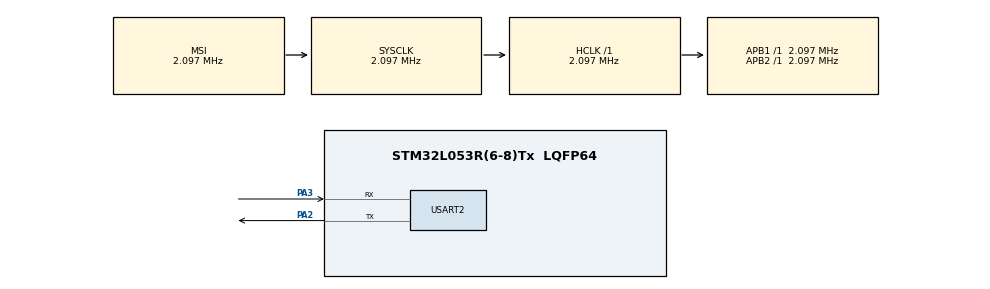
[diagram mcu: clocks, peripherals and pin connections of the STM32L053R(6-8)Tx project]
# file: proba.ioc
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Dma.Request0=USART2_RX
Dma.USART2_RX.0.Direction=DMA_PERIPH_TO_MEMORY
Dma.USART2_RX.0.Instance=DMA1_Channel5
Dma.USART2_RX.0.MemDataAlignment=DMA_MDATAALIGN_BYTE
Dma.USART2_RX.0.MemInc=DMA_MINC_ENABLE
Dma.USART2_RX.0.Mode=DMA_NORMAL
Dma.USART2_RX.0.PeriphDataAlignment=DMA_PDATAALIGN_BYTE
Dma.USART2_RX.0.PeriphInc=DMA_PINC_DISABLE
Dma.USART2_RX.0.Priority=DMA_PRIORITY_LOW
Mcu.Family=STM32L0
Mcu.Name=STM32L053R(6-8)Tx
Mcu.Package=LQFP64
NVIC.DMA1_Channel4_5_6_7_IRQn=true\:0\:0\:false\:false\:true\:false\:true\:true
NVIC.USART2_IRQn=true\:0\:0\:false\:false\:true\:true\:true\:true
PA13.Mode=Serial_Wire
PA13.Signal=SYS_SWDIO
PA14.Mode=Serial_Wire
PA14.Signal=SYS_SWCLK
PA2.Mode=Asynchronous
PA2.Signal=USART2_TX
PA3.Mode=Asynchronous
PA3.Signal=USART2_RX
PC14-OSC32_IN.Mode=LSE-External-Oscillator
PC14-OSC32_IN.Signal=RCC_OSC32_IN
PC15-OSC32_OUT.Mode=LSE-External-Oscillator
PC15-OSC32_OUT.Signal=RCC_OSC32_OUT
PH0-OSC_IN.Mode=HSE-External-Oscillator
PH0-OSC_IN.Signal=RCC_OSC_IN
PH1-OSC_OUT.Mode=HSE-External-Oscillator
PH1-OSC_OUT.Signal=RCC_OSC_OUT
ProjectManager.HeapSize=0x200
ProjectManager.StackSize=0x400
ProjectManager.TargetToolchain=STM32CubeIDE
RCC.AHBFreq_Value=2097000
RCC.APB1Freq_Value=2097000
RCC.APB1TimFreq_Value=2097000
RCC.APB2Freq_Value=2097000
RCC.APB2TimFreq_Value=2097000
RCC.HCLKFreq_Value=2097000
RCC.HSE_VALUE=8000000
RCC.HSI16_VALUE=16000000
RCC.HSI48_VALUE=48000000
RCC.HSI_VALUE=16000000
RCC.MSI_VALUE=2097000
RCC.RTCClockSelection=RCC_RTCCLKSOURCE_LSE
RCC.SYSCLKFreq_VALUE=2097000
RCC.VCOOutputFreq_Value=48000000
RTC.Date=5
RTC.Hours=11
RTC.Minutes=11
RTC.Month=RTC_MONTH_OCTOBER
RTC.Seconds=11
RTC.WeekDay=RTC_WEEKDAY_WEDNESDAY
USART2.VirtualMode-Asynchronous=VM_ASYNC
VP_RTC_VS_RTC_Activate.Mode=RTC_Enabled
VP_RTC_VS_RTC_Calendar.Mode=RTC_Calendar
board=custom

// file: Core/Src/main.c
/* USER CODE BEGIN Header */
/**
  ******************************************************************************
  * @file           : main.c
  * @brief          : Main program body
  ******************************************************************************
  * @attention
  *
  * Copyright (c) 2022 STMicroelectronics.
  * All rights reserved.
  *
  * This software is licensed under terms that can be found in the LICENSE file
  * in the root directory of this software component.
  * If no LICENSE file comes with this software, it is provided AS-IS.
  *
  ******************************************************************************
  */
/* USER CODE END Header */
#include "main.h"

/* USER CODE BEGIN Includes */
#include "string.h"
#include "stdio.h"
/* USER CODE END Includes */

/* USER CODE BEGIN PD */
#define RxBuf_SIZE   15
#define MainBuf_SIZE 20
/* USER CODE END PD */

RTC_HandleTypeDef hrtc;

UART_HandleTypeDef huart2;
DMA_HandleTypeDef hdma_usart2_rx;

/* USER CODE BEGIN PV */
uint8_t RxBuf[RxBuf_SIZE];
uint8_t mainBuf[MainBuf_SIZE];

uint64_t currTick, prevTick; //brojaci milisekundi radi periodickog ispisa
/* USER CODE END PV */

void SystemClock_Config(void);
static void MX_GPIO_Init(void);
static void MX_DMA_Init(void);
static void MX_USART2_UART_Init(void);
static void MX_RTC_Init(void);
/* USER CODE BEGIN PFP */
static void printCurrTime(void); //pozivanjem funkcije izvrsava se dohvacanje trenutnog vremena te ispis preko UARTa u lijepom formatu
static void setTime(int, int, int); //pozivanjem funkcije postavljamo sat predajuci joj sate, minute i sekunde
/* USER CODE END PFP */

int main(void)
{

  /* MCU Configuration--------------------------------------------------------*/

  /* Reset of all peripherals, Initializes the Flash interface and the Systick. */
  HAL_Init();

  /* Configure the system clock */
  SystemClock_Config();

  /* Initialize all configured peripherals */
  MX_GPIO_Init();
  MX_DMA_Init();
  MX_USART2_UART_Init();
  MX_RTC_Init();
  /* USER CODE BEGIN 2 */

  uint8_t test[] = "To set clock enter SET hh:mm:ss\n\rTo see clock enter SHOW CLOCK\n\r";
  HAL_UART_Transmit(&huart2, test, sizeof(test), 100);

  HAL_UARTEx_ReceiveToIdle_DMA(&huart2, RxBuf, RxBuf_SIZE);
  __HAL_DMA_DISABLE_IT(&hdma_usart2_rx, DMA_IT_HT);

  currTick = prevTick = (uint64_t)HAL_GetTick();

  /* USER CODE END 2 */

  /* Infinite loop */
  /* USER CODE BEGIN WHILE */
  while (1)
  {
	  //periodicki ispis sata svake minute
	  currTick = (uint64_t)HAL_GetTick();
	  if(currTick - prevTick >= 60 * 1000)
	  {
		  printCurrTime();
		  prevTick = currTick;
	  }

	  //ispis ako je korisnik unio SHOW CLOCK
	  if(strstr(mainBuf, "SHOW CLOCK")) //provjeravamo buffer jer sve sto korisnik unese spremamo u buffer
	  {
		  printCurrTime();
		  memset(mainBuf, '\0', 20); //postavljanje cijelog buffera na 0 kako bi se ispis izvrsio samo jednom
	  }

	  //postavljanje sata

	  /* za podesavanje sata bez navodnika unijeti: "SET hh:mm:ss"
	   * gdje hh predstavlja sate 0 - 23,
	   * mm predstavlja minute 0 - 59,
	   * ss predstavlja sekunde 0 - 59,
	   * nije potrebno unijeti 0 ako je broj jednoznamenkast
	   *  */

	  char setText[5]; //samo zato da bi sscanf mogao procitati unos u zeljenom formatu
	  int h, m, s; //sati, minute i sekunde za postavljanje

	  sscanf(mainBuf, "%s %d:%d:%d", setText, &h, &m, &s); //ono sto korisnik unese nalazi se u main bufferu i zato citamo iz njega

	  if(strstr(setText, "SET"))//ako je korisnik unio kljucnu rijec SET
	  {
		  if(h >= 0 && h < 24 && m >= 0 && m < 60 && s >= 0 && s < 60) //ako je ispravan format datuma, nemoze biti 25:60:60 i veci
		  {
			  setTime(h, m, s); //postavljanje sata
			  memset(setText, '\0', 5); //ciscenje memorije jer bi inace uvijet uvijek bio zadovoljen i konstantno bi se postavljalo to vrijeme

			  /*
			  Ako sscanf dobije npr. SET 11:22 prvi uvijet ce biti zadovoljen, brojeve 11 i 22
			  ce pohraniti u varijable h i m, dok ce sekunde ostati one koje su bile zadnji put kad se namjestalo
			  ili ako se odmah unese neispravan datum u obliku SET XX:XX, sekunde ce brojiti dalje i nece se postaviti.
			  Da bi drugi uvjet u tom slucaju bio nezadovoljen, postavljena je vrijednost koja je nedozvoljena
			  da nebi doslo do namjestanja sata ukoliko nisu zadani svi parametri. Posto je u pitanju logicko i,
			  dovoljan je da jedan od njih nebude tocan i zato postavljamo samo sekunde na -1.
			  */

			  s = -1;
		  }
	  }

    /* USER CODE END WHILE */

  }
}

void SystemClock_Config(void)
{
  RCC_OscInitTypeDef RCC_OscInitStruct = {0};
  RCC_ClkInitTypeDef RCC_ClkInitStruct = {0};
  RCC_PeriphCLKInitTypeDef PeriphClkInit = {0};

  /** Configure the main internal regulator output voltage
  */
  __HAL_PWR_VOLTAGESCALING_CONFIG(PWR_REGULATOR_VOLTAGE_SCALE1);

  /** Configure LSE Drive Capability
  */
  HAL_PWR_EnableBkUpAccess();
  __HAL_RCC_LSEDRIVE_CONFIG(RCC_LSEDRIVE_LOW);

  /** Initializes the RCC Oscillators according to the specified parameters
  * in the RCC_OscInitTypeDef structure.
  */
  RCC_OscInitStruct.OscillatorType = RCC_OSCILLATORTYPE_LSE|RCC_OSCILLATORTYPE_MSI;
  RCC_OscInitStruct.LSEState = RCC_LSE_ON;
  RCC_OscInitStruct.MSIState = RCC_MSI_ON;
  RCC_OscInitStruct.MSICalibrationValue = 0;
  RCC_OscInitStruct.MSIClockRange = RCC_MSIRANGE_5;
  RCC_OscInitStruct.PLL.PLLState = RCC_PLL_NONE;
  if (HAL_RCC_OscConfig(&RCC_OscInitStruct) != HAL_OK)
  {
    Error_Handler();
  }

  /** Initializes the CPU, AHB and APB buses clocks
  */
  RCC_ClkInitStruct.ClockType = RCC_CLOCKTYPE_HCLK|RCC_CLOCKTYPE_SYSCLK
                              |RCC_CLOCKTYPE_PCLK1|RCC_CLOCKTYPE_PCLK2;
  RCC_ClkInitStruct.SYSCLKSource = RCC_SYSCLKSOURCE_MSI;
  RCC_ClkInitStruct.AHBCLKDivider = RCC_SYSCLK_DIV1;
  RCC_ClkInitStruct.APB1CLKDivider = RCC_HCLK_DIV1;
  RCC_ClkInitStruct.APB2CLKDivider = RCC_HCLK_DIV1;

  if (HAL_RCC_ClockConfig(&RCC_ClkInitStruct, FLASH_LATENCY_0) != HAL_OK)
  {
    Error_Handler();
  }
  PeriphClkInit.PeriphClockSelection = RCC_PERIPHCLK_USART2|RCC_PERIPHCLK_RTC;
  PeriphClkInit.Usart2ClockSelection = RCC_USART2CLKSOURCE_PCLK1;
  PeriphClkInit.RTCClockSelection = RCC_RTCCLKSOURCE_LSE;
  if (HAL_RCCEx_PeriphCLKConfig(&PeriphClkInit) != HAL_OK)
  {
    Error_Handler();
  }
}

static void MX_RTC_Init(void)
{

  RTC_TimeTypeDef sTime = {0};
  RTC_DateTypeDef sDate = {0};

  /** Initialize RTC Only
  */
  hrtc.Instance = RTC;
  hrtc.Init.HourFormat = RTC_HOURFORMAT_24;
  hrtc.Init.AsynchPrediv = 127;
  hrtc.Init.SynchPrediv = 255;
  hrtc.Init.OutPut = RTC_OUTPUT_DISABLE;
  hrtc.Init.OutPutRemap = RTC_OUTPUT_REMAP_NONE;
  hrtc.Init.OutPutPolarity = RTC_OUTPUT_POLARITY_HIGH;
  hrtc.Init.OutPutType = RTC_OUTPUT_TYPE_OPENDRAIN;
  if (HAL_RTC_Init(&hrtc) != HAL_OK)
  {
    Error_Handler();
  }

  /** Initialize RTC and set the Time and Date
  */
  sTime.Hours = 0x11;
  sTime.Minutes = 0x11;
  sTime.Seconds = 0x11;
  sTime.DayLightSaving = RTC_DAYLIGHTSAVING_NONE;
  sTime.StoreOperation = RTC_STOREOPERATION_RESET;
  if (HAL_RTC_SetTime(&hrtc, &sTime, RTC_FORMAT_BCD) != HAL_OK)
  {
    Error_Handler();
  }
  sDate.WeekDay = RTC_WEEKDAY_WEDNESDAY;
  sDate.Month = RTC_MONTH_OCTOBER;
  sDate.Date = 0x5;
  sDate.Year = 0x0;

  if (HAL_RTC_SetDate(&hrtc, &sDate, RTC_FORMAT_BCD) != HAL_OK)
  {
    Error_Handler();
  }

}

static void MX_USART2_UART_Init(void)
{

  huart2.Instance = USART2;
  huart2.Init.BaudRate = 115200;
  huart2.Init.WordLength = UART_WORDLENGTH_8B;
  huart2.Init.StopBits = UART_STOPBITS_1;
  huart2.Init.Parity = UART_PARITY_NONE;
  huart2.Init.Mode = UART_MODE_TX_RX;
  huart2.Init.HwFlowCtl = UART_HWCONTROL_NONE;
  huart2.Init.OverSampling = UART_OVERSAMPLING_16;
  huart2.Init.OneBitSampling = UART_ONE_BIT_SAMPLE_DISABLE;
  huart2.AdvancedInit.AdvFeatureInit = UART_ADVFEATURE_NO_INIT;
  if (HAL_UART_Init(&huart2) != HAL_OK)
  {
    Error_Handler();
  }

}

static void MX_DMA_Init(void)
{

  /* DMA controller clock enable */
  __HAL_RCC_DMA1_CLK_ENABLE();

  /* DMA interrupt init */
  /* DMA1_Channel4_5_6_7_IRQn interrupt configuration */
  HAL_NVIC_SetPriority(DMA1_Channel4_5_6_7_IRQn, 0, 0);
  HAL_NVIC_EnableIRQ(DMA1_Channel4_5_6_7_IRQn);

}

static void MX_GPIO_Init(void)
{

  /* GPIO Ports Clock Enable */
  __HAL_RCC_GPIOC_CLK_ENABLE();
  __HAL_RCC_GPIOH_CLK_ENABLE();
  __HAL_RCC_GPIOA_CLK_ENABLE();

}

/* USER CODE BEGIN 4 */
void HAL_UARTEx_RxEventCallback(UART_HandleTypeDef *huart, uint16_t Size)
{
  /* Prevent unused argument(s) compilation warning */
  UNUSED(huart);
  UNUSED(Size);

  /* NOTE : This function should not be modified, when the callback is needed,
            the HAL_UARTEx_RxEventCallback can be implemented in the user file.
   */

  if(huart->Instance == USART2)
  {
	  memcpy(mainBuf, RxBuf, Size);

	  HAL_UARTEx_ReceiveToIdle_DMA(&huart2, RxBuf, RxBuf_SIZE);
	  __HAL_DMA_DISABLE_IT(&hdma_usart2_rx, DMA_IT_HT);
  }
}

static void printCurrTime(void)
{
	RTC_TimeTypeDef gTime; //struktura za pohranjivanje dohvacenog vremena
	RTC_DateTypeDef sDate; //struktura za pohranjivanje dohvacenog datuma

	uint8_t currTime[9]; //za ispis vremena u lijepom obliku -> hh:mm:ss

    //dohvacanje trenutnog vremena i datuma
	HAL_RTC_GetTime(&hrtc, &gTime, RTC_FORMAT_BIN);
	HAL_RTC_GetDate(&hrtc, &sDate, RTC_FORMAT_BIN); // samo zato jel bez nece azurirat vrijeme

	//pripremanje trenutnog vremena za ispis u hh:mm:ss obliku u varijablu currTime
	sprintf(currTime, "%02d:%02d:%02d", gTime.Hours, gTime.Minutes, gTime.Seconds);

	//ispis trenutnog vremena u novi red
	HAL_UART_Transmit(&huart2, currTime, sizeof(currTime), 100);
	HAL_UART_Transmit(&huart2, "\n\r", sizeof("\n\r"), 100);

}

static void setTime(int h, int m, int s)
{
	RTC_TimeTypeDef sTime;

	sTime.Seconds = s;
	sTime.Minutes = m;
	sTime.Hours = h;
	sTime.SubSeconds = 0;
	sTime.SecondFraction = 0;
	sTime.DayLightSaving = RTC_DAYLIGHTSAVING_NONE;
	sTime.StoreOperation = RTC_STOREOPERATION_RESET;

	if (HAL_RTC_SetTime(&hrtc, &sTime, RTC_FORMAT_BIN) != HAL_OK)
	{
	  Error_Handler();
	}
}
/* USER CODE END 4 */

void Error_Handler(void)
{
  __disable_irq();
  while (1)
  {
  }
}
